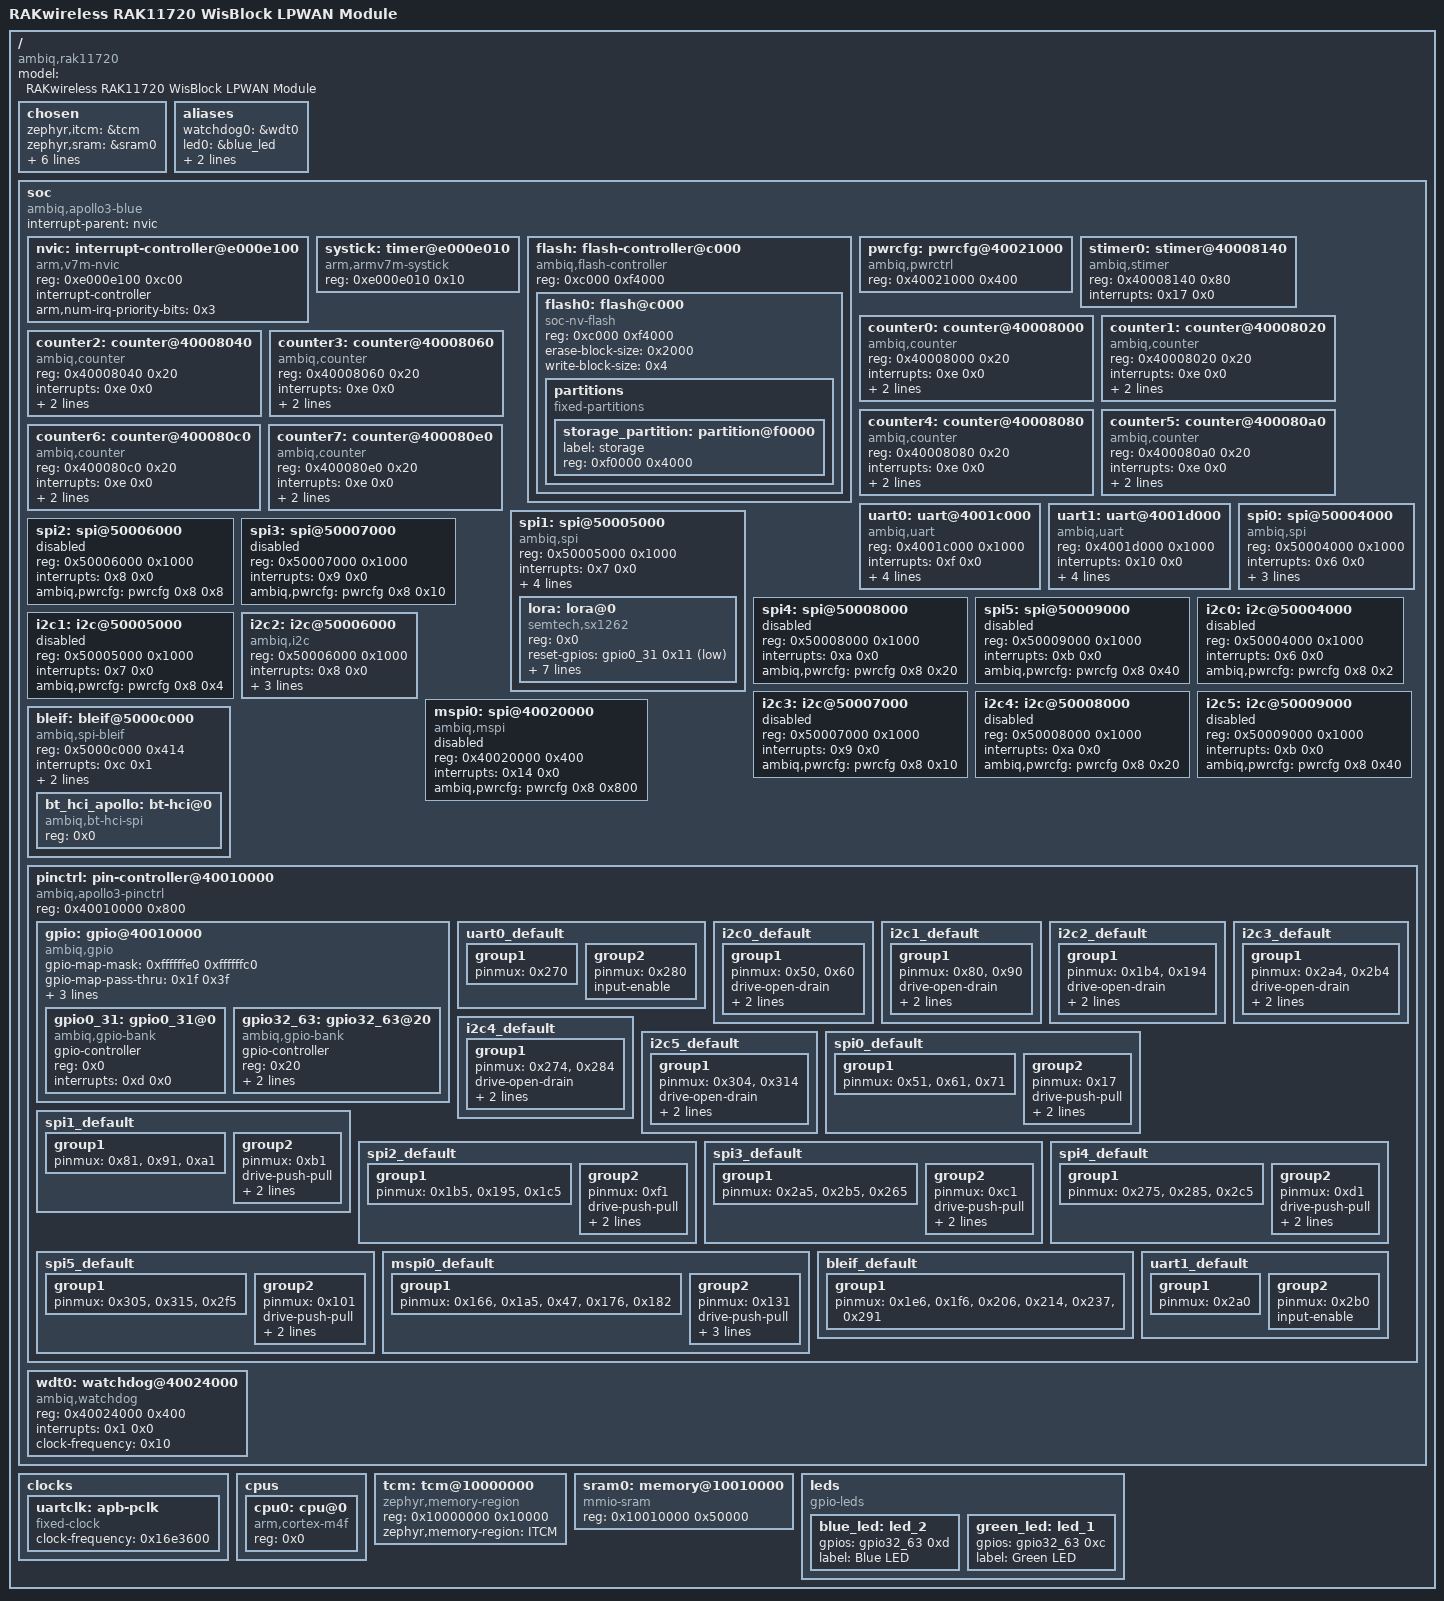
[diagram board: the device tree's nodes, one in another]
/dts-v1/;

/ {
	#address-cells = < 0x1 >;
	#size-cells = < 0x1 >;
	model = "RAKwireless RAK11720 WisBlock LPWAN Module";
	compatible = "ambiq,rak11720";
	chosen {
		zephyr,itcm = &tcm;
		zephyr,sram = &sram0;
		zephyr,flash = &flash0;
		zephyr,console = &uart0;
		zephyr,shell-uart = &uart0;
		zephyr,uart-pipe = &uart0;
		zephyr,flash-controller = &flash;
		zephyr,bt_hci = &bt_hci_apollo;
	};
	aliases {
		watchdog0 = &wdt0;
		led0 = &blue_led;
		led1 = &green_led;
		lora0 = &lora;
	};
	soc {
		#address-cells = < 0x1 >;
		#size-cells = < 0x1 >;
		compatible = "ambiq,apollo3-blue", "ambiq,apollo3x", "simple-bus";
		interrupt-parent = < &nvic >;
		ranges;
		nvic: interrupt-controller@e000e100 {
			#address-cells = < 0x1 >;
			compatible = "arm,v7m-nvic";
			reg = < 0xe000e100 0xc00 >;
			interrupt-controller;
			#interrupt-cells = < 0x2 >;
			arm,num-irq-priority-bits = < 0x3 >;
			phandle = < 0x1 >;
		};
		systick: timer@e000e010 {
			compatible = "arm,armv7m-systick";
			reg = < 0xe000e010 0x10 >;
		};
		flash: flash-controller@c000 {
			compatible = "ambiq,flash-controller";
			reg = < 0xc000 0xf4000 >;
			#address-cells = < 0x1 >;
			#size-cells = < 0x1 >;
			flash0: flash@c000 {
				compatible = "soc-nv-flash";
				reg = < 0xc000 0xf4000 >;
				erase-block-size = < 0x2000 >;
				write-block-size = < 0x4 >;
				partitions {
					compatible = "fixed-partitions";
					#address-cells = < 0x1 >;
					#size-cells = < 0x1 >;
					storage_partition: partition@f0000 {
						label = "storage";
						reg = < 0xf0000 0x4000 >;
					};
				};
			};
		};
		pwrcfg: pwrcfg@40021000 {
			compatible = "ambiq,pwrctrl";
			reg = < 0x40021000 0x400 >;
			#pwrcfg-cells = < 0x2 >;
			phandle = < 0x3 >;
		};
		stimer0: stimer@40008140 {
			compatible = "ambiq,stimer";
			reg = < 0x40008140 0x80 >;
			interrupts = < 0x17 0x0 >;
			status = "okay";
		};
		counter0: counter@40008000 {
			compatible = "ambiq,counter";
			reg = < 0x40008000 0x20 >;
			interrupts = < 0xe 0x0 >;
			clock-frequency = < 0x2dc6c0 >;
			clk-source = < 0x2 >;
			status = "okay";
		};
		counter1: counter@40008020 {
			compatible = "ambiq,counter";
			reg = < 0x40008020 0x20 >;
			interrupts = < 0xe 0x0 >;
			clock-frequency = < 0x2dc6c0 >;
			clk-source = < 0x2 >;
			status = "okay";
		};
		counter2: counter@40008040 {
			compatible = "ambiq,counter";
			reg = < 0x40008040 0x20 >;
			interrupts = < 0xe 0x0 >;
			clock-frequency = < 0x2dc6c0 >;
			clk-source = < 0x2 >;
			status = "okay";
		};
		counter3: counter@40008060 {
			compatible = "ambiq,counter";
			reg = < 0x40008060 0x20 >;
			interrupts = < 0xe 0x0 >;
			clock-frequency = < 0x2dc6c0 >;
			clk-source = < 0x2 >;
			status = "okay";
		};
		counter4: counter@40008080 {
			compatible = "ambiq,counter";
			reg = < 0x40008080 0x20 >;
			interrupts = < 0xe 0x0 >;
			clock-frequency = < 0x2dc6c0 >;
			clk-source = < 0x2 >;
			status = "okay";
		};
		counter5: counter@400080a0 {
			compatible = "ambiq,counter";
			reg = < 0x400080a0 0x20 >;
			interrupts = < 0xe 0x0 >;
			clock-frequency = < 0x2dc6c0 >;
			clk-source = < 0x2 >;
			status = "okay";
		};
		counter6: counter@400080c0 {
			compatible = "ambiq,counter";
			reg = < 0x400080c0 0x20 >;
			interrupts = < 0xe 0x0 >;
			clock-frequency = < 0x2dc6c0 >;
			clk-source = < 0x2 >;
			status = "okay";
		};
		counter7: counter@400080e0 {
			compatible = "ambiq,counter";
			reg = < 0x400080e0 0x20 >;
			interrupts = < 0xe 0x0 >;
			clock-frequency = < 0x2dc6c0 >;
			clk-source = < 0x2 >;
			status = "okay";
		};
		uart0: uart@4001c000 {
			compatible = "ambiq,uart", "arm,pl011";
			reg = < 0x4001c000 0x1000 >;
			interrupts = < 0xf 0x0 >;
			interrupt-names = "UART0";
			status = "okay";
			clocks = < &uartclk >;
			ambiq,pwrcfg = < &pwrcfg 0x8 0x80 >;
			current-speed = < 0x2580 >;
			pinctrl-0 = < &uart0_default >;
			pinctrl-names = "default";
		};
		uart1: uart@4001d000 {
			compatible = "ambiq,uart", "arm,pl011";
			reg = < 0x4001d000 0x1000 >;
			interrupts = < 0x10 0x0 >;
			interrupt-names = "UART1";
			status = "okay";
			clocks = < &uartclk >;
			ambiq,pwrcfg = < &pwrcfg 0x8 0x100 >;
			current-speed = < 0x1c200 >;
			pinctrl-0 = < &uart1_default >;
			pinctrl-names = "default";
		};
		spi0: spi@50004000 {
			reg = < 0x50004000 0x1000 >;
			#address-cells = < 0x1 >;
			#size-cells = < 0x0 >;
			interrupts = < 0x6 0x0 >;
			status = "okay";
			ambiq,pwrcfg = < &pwrcfg 0x8 0x2 >;
			compatible = "ambiq,spi";
			pinctrl-0 = < &spi0_default >;
			pinctrl-names = "default";
			clock-frequency = < 0xf4240 >;
		};
		spi1: spi@50005000 {
			reg = < 0x50005000 0x1000 >;
			#address-cells = < 0x1 >;
			#size-cells = < 0x0 >;
			interrupts = < 0x7 0x0 >;
			status = "okay";
			ambiq,pwrcfg = < &pwrcfg 0x8 0x4 >;
			compatible = "ambiq,spi";
			pinctrl-0 = < &spi1_default >;
			pinctrl-names = "default";
			clock-frequency = < 0xf4240 >;
			cs-gpios = < &gpio0_31 0xb 0x1 >;
			lora: lora@0 {
				compatible = "semtech,sx1262";
				reg = < 0x0 >;
				reset-gpios = < &gpio0_31 0x11 0x1 >;
				busy-gpios = < &gpio0_31 0x10 0x0 >;
				dio1-gpios = < &gpio0_31 0xf 0x0 >;
				antenna-enable-gpios = < &gpio0_31 0x12 0x1 >;
				dio2-tx-enable;
				dio3-tcxo-voltage = < 0x7 >;
				tcxo-power-startup-delay-ms = < 0x5 >;
				spi-max-frequency = < 0xf4240 >;
			};
		};
		spi2: spi@50006000 {
			reg = < 0x50006000 0x1000 >;
			#address-cells = < 0x1 >;
			#size-cells = < 0x0 >;
			interrupts = < 0x8 0x0 >;
			status = "disabled";
			ambiq,pwrcfg = < &pwrcfg 0x8 0x8 >;
		};
		spi3: spi@50007000 {
			reg = < 0x50007000 0x1000 >;
			#address-cells = < 0x1 >;
			#size-cells = < 0x0 >;
			interrupts = < 0x9 0x0 >;
			status = "disabled";
			ambiq,pwrcfg = < &pwrcfg 0x8 0x10 >;
		};
		spi4: spi@50008000 {
			reg = < 0x50008000 0x1000 >;
			#address-cells = < 0x1 >;
			#size-cells = < 0x0 >;
			interrupts = < 0xa 0x0 >;
			status = "disabled";
			ambiq,pwrcfg = < &pwrcfg 0x8 0x20 >;
		};
		spi5: spi@50009000 {
			reg = < 0x50009000 0x1000 >;
			#address-cells = < 0x1 >;
			#size-cells = < 0x0 >;
			interrupts = < 0xb 0x0 >;
			status = "disabled";
			ambiq,pwrcfg = < &pwrcfg 0x8 0x40 >;
		};
		i2c0: i2c@50004000 {
			reg = < 0x50004000 0x1000 >;
			#address-cells = < 0x1 >;
			#size-cells = < 0x0 >;
			interrupts = < 0x6 0x0 >;
			status = "disabled";
			ambiq,pwrcfg = < &pwrcfg 0x8 0x2 >;
		};
		i2c1: i2c@50005000 {
			reg = < 0x50005000 0x1000 >;
			#address-cells = < 0x1 >;
			#size-cells = < 0x0 >;
			interrupts = < 0x7 0x0 >;
			status = "disabled";
			ambiq,pwrcfg = < &pwrcfg 0x8 0x4 >;
		};
		i2c2: i2c@50006000 {
			reg = < 0x50006000 0x1000 >;
			#address-cells = < 0x1 >;
			#size-cells = < 0x0 >;
			interrupts = < 0x8 0x0 >;
			status = "okay";
			ambiq,pwrcfg = < &pwrcfg 0x8 0x8 >;
			compatible = "ambiq,i2c";
			pinctrl-0 = < &i2c2_default >;
			pinctrl-names = "default";
			clock-frequency = < 0x186a0 >;
		};
		i2c3: i2c@50007000 {
			reg = < 0x50007000 0x1000 >;
			#address-cells = < 0x1 >;
			#size-cells = < 0x0 >;
			interrupts = < 0x9 0x0 >;
			status = "disabled";
			ambiq,pwrcfg = < &pwrcfg 0x8 0x10 >;
		};
		i2c4: i2c@50008000 {
			reg = < 0x50008000 0x1000 >;
			#address-cells = < 0x1 >;
			#size-cells = < 0x0 >;
			interrupts = < 0xa 0x0 >;
			status = "disabled";
			ambiq,pwrcfg = < &pwrcfg 0x8 0x20 >;
		};
		i2c5: i2c@50009000 {
			reg = < 0x50009000 0x1000 >;
			#address-cells = < 0x1 >;
			#size-cells = < 0x0 >;
			interrupts = < 0xb 0x0 >;
			status = "disabled";
			ambiq,pwrcfg = < &pwrcfg 0x8 0x40 >;
		};
		mspi0: spi@40020000 {
			compatible = "ambiq,mspi";
			reg = < 0x40020000 0x400 >;
			interrupts = < 0x14 0x0 >;
			#address-cells = < 0x1 >;
			#size-cells = < 0x0 >;
			status = "disabled";
			ambiq,pwrcfg = < &pwrcfg 0x8 0x800 >;
		};
		bleif: bleif@5000c000 {
			compatible = "ambiq,spi-bleif";
			reg = < 0x5000c000 0x414 >;
			interrupts = < 0xc 0x1 >;
			#address-cells = < 0x1 >;
			#size-cells = < 0x0 >;
			status = "okay";
			ambiq,pwrcfg = < &pwrcfg 0x8 0x8000 >;
			pinctrl-0 = < &bleif_default >;
			pinctrl-names = "default";
			bt_hci_apollo: bt-hci@0 {
				compatible = "ambiq,bt-hci-spi";
				reg = < 0x0 >;
			};
		};
		pinctrl: pin-controller@40010000 {
			compatible = "ambiq,apollo3-pinctrl";
			reg = < 0x40010000 0x800 >;
			#address-cells = < 0x1 >;
			#size-cells = < 0x0 >;
			gpio: gpio@40010000 {
				compatible = "ambiq,gpio";
				gpio-map-mask = < 0xffffffe0 0xffffffc0 >;
				gpio-map-pass-thru = < 0x1f 0x3f >;
				gpio-map = < 0x0 0x0 &gpio0_31 0x0 0x0 0x20 0x0 &gpio32_63 0x0 0x0 >;
				reg = < 0x40010000 >;
				#gpio-cells = < 0x2 >;
				#address-cells = < 0x1 >;
				#size-cells = < 0x0 >;
				ranges;
				gpio0_31: gpio0_31@0 {
					compatible = "ambiq,gpio-bank";
					gpio-controller;
					#gpio-cells = < 0x2 >;
					reg = < 0x0 >;
					interrupts = < 0xd 0x0 >;
					status = "okay";
					phandle = < 0x8 >;
				};
				gpio32_63: gpio32_63@20 {
					compatible = "ambiq,gpio-bank";
					gpio-controller;
					#gpio-cells = < 0x2 >;
					reg = < 0x20 >;
					interrupts = < 0xd 0x0 >;
					status = "okay";
					ngpios = < 0x12 >;
					phandle = < 0xb >;
				};
			};
			uart0_default: uart0_default {
				phandle = < 0x4 >;
				group1 {
					pinmux = < 0x270 >;
				};
				group2 {
					pinmux = < 0x280 >;
					input-enable;
				};
			};
			i2c0_default: i2c0_default {
				group1 {
					pinmux = < 0x50 >, < 0x60 >;
					drive-open-drain;
					drive-strength = "0.5";
					bias-pull-up;
				};
			};
			i2c1_default: i2c1_default {
				group1 {
					pinmux = < 0x80 >, < 0x90 >;
					drive-open-drain;
					drive-strength = "0.5";
					bias-pull-up;
				};
			};
			i2c2_default: i2c2_default {
				phandle = < 0x9 >;
				group1 {
					pinmux = < 0x1b4 >, < 0x194 >;
					drive-open-drain;
					drive-strength = "0.5";
					bias-pull-up;
				};
			};
			i2c3_default: i2c3_default {
				group1 {
					pinmux = < 0x2a4 >, < 0x2b4 >;
					drive-open-drain;
					drive-strength = "0.5";
					bias-pull-up;
				};
			};
			i2c4_default: i2c4_default {
				group1 {
					pinmux = < 0x274 >, < 0x284 >;
					drive-open-drain;
					drive-strength = "0.5";
					bias-pull-up;
				};
			};
			i2c5_default: i2c5_default {
				group1 {
					pinmux = < 0x304 >, < 0x314 >;
					drive-open-drain;
					drive-strength = "0.5";
					bias-pull-up;
				};
			};
			spi0_default: spi0_default {
				phandle = < 0x6 >;
				group1 {
					pinmux = < 0x51 >, < 0x61 >, < 0x71 >;
				};
				group2 {
					pinmux = < 0x17 >;
					drive-push-pull;
					ambiq,iom-nce-module = < 0x0 >;
					ambiq,iom-num = < 0x0 >;
				};
			};
			spi1_default: spi1_default {
				phandle = < 0x7 >;
				group1 {
					pinmux = < 0x81 >, < 0x91 >, < 0xa1 >;
				};
				group2 {
					pinmux = < 0xb1 >;
					drive-push-pull;
					ambiq,iom-nce-module = < 0x1 >;
					ambiq,iom-num = < 0x1 >;
				};
			};
			spi2_default: spi2_default {
				group1 {
					pinmux = < 0x1b5 >, < 0x195 >, < 0x1c5 >;
				};
				group2 {
					pinmux = < 0xf1 >;
					drive-push-pull;
					ambiq,iom-nce-module = < 0x3 >;
					ambiq,iom-num = < 0x2 >;
				};
			};
			spi3_default: spi3_default {
				group1 {
					pinmux = < 0x2a5 >, < 0x2b5 >, < 0x265 >;
				};
				group2 {
					pinmux = < 0xc1 >;
					drive-push-pull;
					ambiq,iom-nce-module = < 0x0 >;
					ambiq,iom-num = < 0x3 >;
				};
			};
			spi4_default: spi4_default {
				group1 {
					pinmux = < 0x275 >, < 0x285 >, < 0x2c5 >;
				};
				group2 {
					pinmux = < 0xd1 >;
					drive-push-pull;
					ambiq,iom-nce-module = < 0x1 >;
					ambiq,iom-num = < 0x4 >;
				};
			};
			spi5_default: spi5_default {
				group1 {
					pinmux = < 0x305 >, < 0x315 >, < 0x2f5 >;
				};
				group2 {
					pinmux = < 0x101 >;
					drive-push-pull;
					ambiq,iom-nce-module = < 0x0 >;
					ambiq,iom-num = < 0x5 >;
				};
			};
			mspi0_default: mspi0_default {
				group1 {
					pinmux = < 0x166 >, < 0x1a5 >, < 0x47 >, < 0x176 >, < 0x182 >;
				};
				group2 {
					pinmux = < 0x131 >;
					drive-push-pull;
					drive-strength = "0.5";
					ambiq,iom-nce-module = < 0x0 >;
					ambiq,iom-num = < 0x6 >;
				};
			};
			bleif_default: bleif_default {
				phandle = < 0xa >;
				group1 {
					pinmux = < 0x1e6 >, < 0x1f6 >, < 0x206 >, < 0x214 >, < 0x237 >, < 0x291 >;
				};
			};
			uart1_default: uart1_default {
				phandle = < 0x5 >;
				group1 {
					pinmux = < 0x2a0 >;
				};
				group2 {
					pinmux = < 0x2b0 >;
					input-enable;
				};
			};
		};
		wdt0: watchdog@40024000 {
			compatible = "ambiq,watchdog";
			reg = < 0x40024000 0x400 >;
			interrupts = < 0x1 0x0 >;
			clock-frequency = < 0x10 >;
			status = "okay";
		};
	};
	clocks {
		uartclk: apb-pclk {
			compatible = "fixed-clock";
			clock-frequency = < 0x16e3600 >;
			#clock-cells = < 0x0 >;
			phandle = < 0x2 >;
		};
	};
	cpus {
		#address-cells = < 0x1 >;
		#size-cells = < 0x0 >;
		cpu0: cpu@0 {
			compatible = "arm,cortex-m4f";
			reg = < 0x0 >;
		};
	};
	tcm: tcm@10000000 {
		compatible = "zephyr,memory-region";
		reg = < 0x10000000 0x10000 >;
		zephyr,memory-region = "ITCM";
	};
	sram0: memory@10010000 {
		compatible = "mmio-sram";
		reg = < 0x10010000 0x50000 >;
	};
	leds {
		compatible = "gpio-leds";
		blue_led: led_2 {
			gpios = < &gpio32_63 0xd 0x0 >;
			label = "Blue LED";
		};
		green_led: led_1 {
			gpios = < &gpio32_63 0xc 0x0 >;
			label = "Green LED";
		};
	};
};
